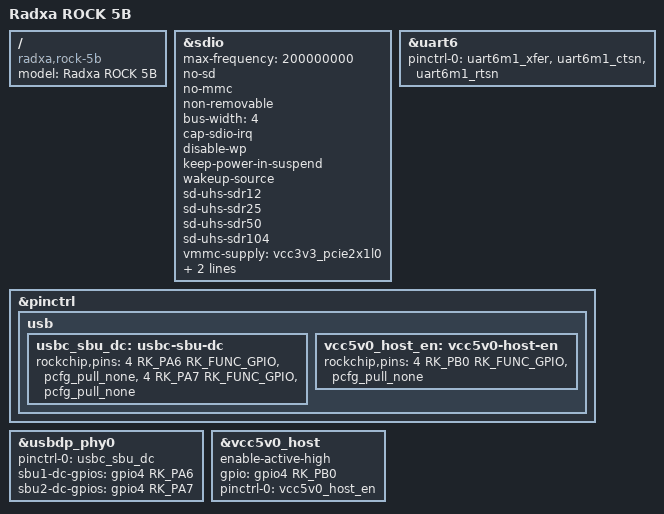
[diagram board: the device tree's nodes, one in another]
// SPDX-License-Identifier: (GPL-2.0+ OR MIT)

/dts-v1/;

#include "rk3588-rock-5b.dtsi"

/ {
	model = "Radxa ROCK 5B";
	compatible = "radxa,rock-5b", "rockchip,rk3588";
};

&sdio {
	max-frequency = <200000000>;
	no-sd;
	no-mmc;
	non-removable;
	bus-width = <4>;
	cap-sdio-irq;
	disable-wp;
	keep-power-in-suspend;
	wakeup-source;
	sd-uhs-sdr12;
	sd-uhs-sdr25;
	sd-uhs-sdr50;
	sd-uhs-sdr104;
	vmmc-supply = <&vcc3v3_pcie2x1l0>;
	vqmmc-supply = <&vcc_1v8_s3>;
	pinctrl-names = "default";
	pinctrl-0 = <&sdiom0_pins>;
	status = "okay";
};

&uart6 {
	pinctrl-names = "default";
	pinctrl-0 = <&uart6m1_xfer &uart6m1_ctsn &uart6m1_rtsn>;
	status = "okay";
};

&pinctrl {
	usb {
		usbc_sbu_dc: usbc-sbu-dc {
			rockchip,pins = <4 RK_PA6 RK_FUNC_GPIO &pcfg_pull_none>,
					<4 RK_PA7 RK_FUNC_GPIO &pcfg_pull_none>;
		};

		vcc5v0_host_en: vcc5v0-host-en {
			rockchip,pins = <4 RK_PB0 RK_FUNC_GPIO &pcfg_pull_none>;
		};
	};
};

&usbdp_phy0 {
	pinctrl-names = "default";
	pinctrl-0 = <&usbc_sbu_dc>;
	sbu1-dc-gpios = <&gpio4 RK_PA6 GPIO_ACTIVE_HIGH>;
	sbu2-dc-gpios = <&gpio4 RK_PA7 GPIO_ACTIVE_HIGH>;
};

&vcc5v0_host {
	enable-active-high;
	gpio = <&gpio4 RK_PB0 GPIO_ACTIVE_HIGH>;
	pinctrl-names = "default";
	pinctrl-0 = <&vcc5v0_host_en>;
};
